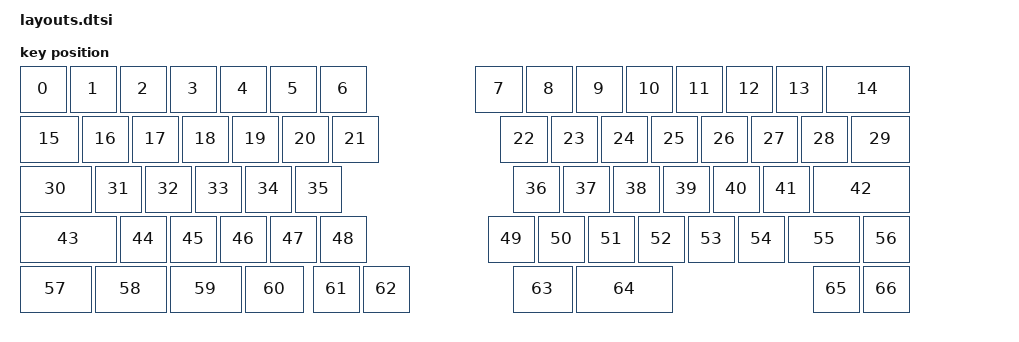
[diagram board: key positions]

#include <physical_layouts.dtsi>
/ {
    physical_layout0: physical_layout0 {
        compatible = "zmk,physical-layout";
        display-name = "Layout";
        keys
            = <&key_physical_attrs 100 100 (-37) 38 0 0 0>
			,<&key_physical_attrs 100 100 63 38 0 0 0>
			,<&key_physical_attrs 100 100 163 38 0 0 0>
			,<&key_physical_attrs 100 100 263 38 0 0 0>
			,<&key_physical_attrs 100 100 363 38 0 0 0>
			,<&key_physical_attrs 100 100 463 38 0 0 0>
			,<&key_physical_attrs 100 100 563 38 0 0 0>
			,<&key_physical_attrs 100 100 875 38 0 0 0>
			,<&key_physical_attrs 100 100 975 38 0 0 0>
			,<&key_physical_attrs 100 100 1075 38 0 0 0>
			,<&key_physical_attrs 100 100 1175 38 0 0 0>
			,<&key_physical_attrs 100 100 1275 38 0 0 0>
			,<&key_physical_attrs 100 100 1375 38 0 0 0>
			,<&key_physical_attrs 100 100 1475 38 0 0 0>
			,<&key_physical_attrs 175 100 1575 38 0 0 0>
			,<&key_physical_attrs 125 100 (-37) 138 0 0 0>
			,<&key_physical_attrs 100 100 88 138 0 0 0>
			,<&key_physical_attrs 100 100 188 138 0 0 0>
			,<&key_physical_attrs 100 100 288 138 0 0 0>
			,<&key_physical_attrs 100 100 388 138 0 0 0>
			,<&key_physical_attrs 100 100 488 138 0 0 0>
			,<&key_physical_attrs 100 100 588 138 0 0 0>
			,<&key_physical_attrs 100 100 925 138 0 0 0>
			,<&key_physical_attrs 100 100 1025 138 0 0 0>
			,<&key_physical_attrs 100 100 1125 138 0 0 0>
			,<&key_physical_attrs 100 100 1225 138 0 0 0>
			,<&key_physical_attrs 100 100 1325 138 0 0 0>
			,<&key_physical_attrs 100 100 1425 138 0 0 0>
			,<&key_physical_attrs 100 100 1525 138 0 0 0>
			,<&key_physical_attrs 125 100 1625 138 0 0 0>
			,<&key_physical_attrs 150 100 (-37) 238 0 0 0>
			,<&key_physical_attrs 100 100 113 238 0 0 0>
			,<&key_physical_attrs 100 100 213 238 0 0 0>
			,<&key_physical_attrs 100 100 313 238 0 0 0>
			,<&key_physical_attrs 100 100 413 238 0 0 0>
			,<&key_physical_attrs 100 100 513 238 0 0 0>
			,<&key_physical_attrs 100 100 950 238 0 0 0>
			,<&key_physical_attrs 100 100 1050 238 0 0 0>
			,<&key_physical_attrs 100 100 1150 238 0 0 0>
			,<&key_physical_attrs 100 100 1250 238 0 0 0>
			,<&key_physical_attrs 100 100 1350 238 0 0 0>
			,<&key_physical_attrs 100 100 1450 238 0 0 0>
			,<&key_physical_attrs 200 100 1550 238 0 0 0>
			,<&key_physical_attrs 200 100 (-37) 338 0 0 0>
			,<&key_physical_attrs 100 100 163 338 0 0 0>
			,<&key_physical_attrs 100 100 263 338 0 0 0>
			,<&key_physical_attrs 100 100 363 338 0 0 0>
			,<&key_physical_attrs 100 100 463 338 0 0 0>
			,<&key_physical_attrs 100 100 563 338 0 0 0>
			,<&key_physical_attrs 100 100 900 338 0 0 0>
			,<&key_physical_attrs 100 100 1000 338 0 0 0>
			,<&key_physical_attrs 100 100 1100 338 0 0 0>
			,<&key_physical_attrs 100 100 1200 338 0 0 0>
			,<&key_physical_attrs 100 100 1300 338 0 0 0>
			,<&key_physical_attrs 100 100 1400 338 0 0 0>
			,<&key_physical_attrs 150 100 1500 338 0 0 0>
			,<&key_physical_attrs 100 100 1650 338 0 0 0>
			,<&key_physical_attrs 150 100 (-37) 438 0 0 0>
			,<&key_physical_attrs 150 100 113 438 0 0 0>
			,<&key_physical_attrs 150 100 263 438 0 0 0>
			,<&key_physical_attrs 125 100 413 438 0 0 0>
			,<&key_physical_attrs 100 100 550 438 0 0 0>
			,<&key_physical_attrs 100 100 650 438 0 0 0>
			,<&key_physical_attrs 125 100 950 438 0 0 0>
			,<&key_physical_attrs 200 100 1075 438 0 0 0>
			,<&key_physical_attrs 100 100 1550 438 0 0 0>
			,<&key_physical_attrs 100 100 1650 438 0 0 0>
            ;
    };
};
    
